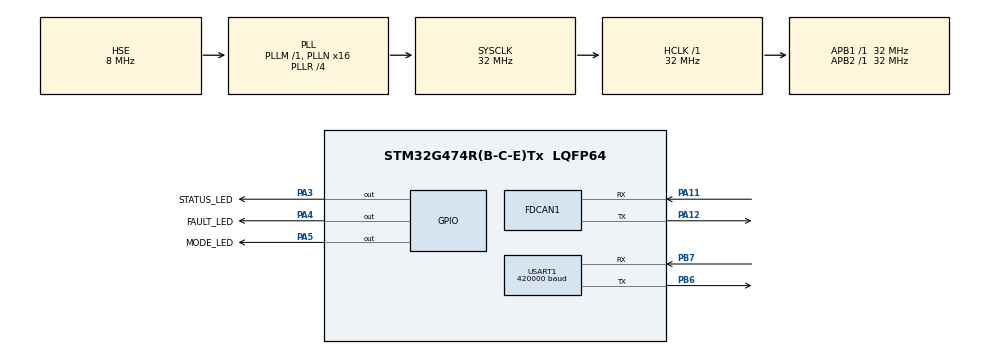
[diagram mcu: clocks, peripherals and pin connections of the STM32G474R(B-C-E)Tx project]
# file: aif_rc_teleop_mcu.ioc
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FDCAN1.CalculateBaudRateNominal=500000
FDCAN1.CalculateTimeBitNominal=2000
FDCAN1.CalculateTimeQuantumNominal=125.0
FDCAN1.DataSyncJumpWidth=2
FDCAN1.NominalPrescaler=1
FDCAN1.NominalTimeSeg1=13
FDCAN1.NominalTimeSeg2=2
FDCAN1.StdFiltersNbr=1
Mcu.Family=STM32G4
Mcu.Name=STM32G474R(B-C-E)Tx
Mcu.Package=LQFP64
NVIC.FDCAN1_IT0_IRQn=true\:0\:0\:false\:false\:true\:true\:true\:true
NVIC.PriorityGroup=NVIC_PRIORITYGROUP_4
NVIC.USART1_IRQn=true\:0\:0\:false\:false\:true\:true\:true\:true
PA11.Mode=FDCAN_Activate
PA11.Signal=FDCAN1_RX
PA12.Mode=FDCAN_Activate
PA12.Signal=FDCAN1_TX
PA13.Mode=Serial_Wire
PA13.Signal=SYS_JTMS-SWDIO
PA14.Mode=Serial_Wire
PA14.Signal=SYS_JTCK-SWCLK
PA3.GPIO_Label=STATUS_LED
PA3.Signal=GPIO_Output
PA4.GPIO_Label=FAULT_LED
PA4.Signal=GPIO_Output
PA5.GPIO_Label=MODE_LED
PA5.Signal=GPIO_Output
PB6.Mode=Asynchronous
PB6.Signal=USART1_TX
PB7.Mode=Asynchronous
PB7.Signal=USART1_RX
PF0-OSC_IN.Mode=HSE-External-Oscillator
PF0-OSC_IN.Signal=RCC_OSC_IN
PF1-OSC_OUT.Mode=HSE-External-Oscillator
PF1-OSC_OUT.Signal=RCC_OSC_OUT
ProjectManager.HeapSize=0x200
ProjectManager.StackSize=0x400
ProjectManager.TargetToolchain=STM32CubeIDE
RCC.ADC12Freq_Value=32000000
RCC.ADC345Freq_Value=32000000
RCC.AHBFreq_Value=32000000
RCC.APB1Freq_Value=32000000
RCC.APB1TimFreq_Value=32000000
RCC.APB2Freq_Value=32000000
RCC.APB2TimFreq_Value=32000000
RCC.CortexFreq_Value=32000000
RCC.EXTERNAL_CLOCK_VALUE=12288000
RCC.FDCANCLockSelection=RCC_FDCANCLKSOURCE_HSE
RCC.HCLKFreq_Value=32000000
RCC.HSE_VALUE=8000000
RCC.HSI48_VALUE=48000000
RCC.HSI_VALUE=16000000
RCC.LSE_VALUE=32768
RCC.PLLN=16
RCC.PLLR=RCC_PLLR_DIV4
RCC.PLLSourceVirtual=RCC_PLLSOURCE_HSE
RCC.SYSCLKFreq_VALUE=32000000
RCC.SYSCLKSource=RCC_SYSCLKSOURCE_PLLCLK
RCC.USBFreq_Value=64000000
RCC.VCOOutputFreq_Value=128000000
USART1.BaudRate=420000
USART1.Mode=MODE_RX
USART1.VirtualMode-Asynchronous=VM_ASYNC
VP_SYS_VS_DBSignals.Mode=DisableDeadBatterySignals
board=custom

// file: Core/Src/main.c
/* USER CODE BEGIN Header */
/**
  ******************************************************************************
  * @file           : main.c
  * @brief          : Main program body
  ******************************************************************************
  * @attention
  *
  * Copyright (c) 2026 STMicroelectronics.
  * All rights reserved.
  *
  * This software is licensed under terms that can be found in the LICENSE file
  * in the root directory of this software component.
  * If no LICENSE file comes with this software, it is provided AS-IS.
  *
  ******************************************************************************
  */
/* USER CODE END Header */
#include "main.h"

/* USER CODE BEGIN Includes */
#include "app.h"

/* USER CODE END Includes */

FDCAN_HandleTypeDef hfdcan1;

UART_HandleTypeDef huart1;

void SystemClock_Config(void);
static void MX_GPIO_Init(void);
static void MX_FDCAN1_Init(void);
static void MX_USART1_UART_Init(void);

int main(void)
{

  /* MCU Configuration--------------------------------------------------------*/

  /* Reset of all peripherals, Initializes the Flash interface and the Systick. */
  HAL_Init();

  /* Configure the system clock */
  SystemClock_Config();

  /* Initialize all configured peripherals */
  MX_GPIO_Init();
  MX_FDCAN1_Init();
  MX_USART1_UART_Init();
  /* USER CODE BEGIN 2 */
  app_init();

  /* USER CODE END 2 */

  /* Infinite loop */
  while (1)
  {

    /* USER CODE BEGIN 3 */
    app_loop();
  }
  /* USER CODE END 3 */
}

void SystemClock_Config(void)
{
  RCC_OscInitTypeDef RCC_OscInitStruct = {0};
  RCC_ClkInitTypeDef RCC_ClkInitStruct = {0};

  /** Configure the main internal regulator output voltage
  */
  HAL_PWREx_ControlVoltageScaling(PWR_REGULATOR_VOLTAGE_SCALE1);

  /** Initializes the RCC Oscillators according to the specified parameters
  * in the RCC_OscInitTypeDef structure.
  */
  RCC_OscInitStruct.OscillatorType = RCC_OSCILLATORTYPE_HSE;
  RCC_OscInitStruct.HSEState = RCC_HSE_ON;
  RCC_OscInitStruct.PLL.PLLState = RCC_PLL_ON;
  RCC_OscInitStruct.PLL.PLLSource = RCC_PLLSOURCE_HSE;
  RCC_OscInitStruct.PLL.PLLM = RCC_PLLM_DIV1;
  RCC_OscInitStruct.PLL.PLLN = 16;
  RCC_OscInitStruct.PLL.PLLP = RCC_PLLP_DIV2;
  RCC_OscInitStruct.PLL.PLLQ = RCC_PLLQ_DIV2;
  RCC_OscInitStruct.PLL.PLLR = RCC_PLLR_DIV4;
  if (HAL_RCC_OscConfig(&RCC_OscInitStruct) != HAL_OK)
  {
    Error_Handler();
  }

  /** Initializes the CPU, AHB and APB buses clocks
  */
  RCC_ClkInitStruct.ClockType = RCC_CLOCKTYPE_HCLK|RCC_CLOCKTYPE_SYSCLK
                              |RCC_CLOCKTYPE_PCLK1|RCC_CLOCKTYPE_PCLK2;
  RCC_ClkInitStruct.SYSCLKSource = RCC_SYSCLKSOURCE_PLLCLK;
  RCC_ClkInitStruct.AHBCLKDivider = RCC_SYSCLK_DIV1;
  RCC_ClkInitStruct.APB1CLKDivider = RCC_HCLK_DIV1;
  RCC_ClkInitStruct.APB2CLKDivider = RCC_HCLK_DIV1;

  if (HAL_RCC_ClockConfig(&RCC_ClkInitStruct, FLASH_LATENCY_1) != HAL_OK)
  {
    Error_Handler();
  }
}

static void MX_FDCAN1_Init(void)
{

  hfdcan1.Instance = FDCAN1;
  hfdcan1.Init.ClockDivider = FDCAN_CLOCK_DIV1;
  hfdcan1.Init.FrameFormat = FDCAN_FRAME_CLASSIC;
  hfdcan1.Init.Mode = FDCAN_MODE_NORMAL;
  hfdcan1.Init.AutoRetransmission = DISABLE;
  hfdcan1.Init.TransmitPause = DISABLE;
  hfdcan1.Init.ProtocolException = DISABLE;
  hfdcan1.Init.NominalPrescaler = 1;
  hfdcan1.Init.NominalSyncJumpWidth = 1;
  hfdcan1.Init.NominalTimeSeg1 = 13;
  hfdcan1.Init.NominalTimeSeg2 = 2;
  hfdcan1.Init.DataPrescaler = 1;
  hfdcan1.Init.DataSyncJumpWidth = 2;
  hfdcan1.Init.DataTimeSeg1 = 1;
  hfdcan1.Init.DataTimeSeg2 = 1;
  hfdcan1.Init.StdFiltersNbr = 1;
  hfdcan1.Init.ExtFiltersNbr = 0;
  hfdcan1.Init.TxFifoQueueMode = FDCAN_TX_FIFO_OPERATION;
  if (HAL_FDCAN_Init(&hfdcan1) != HAL_OK)
  {
    Error_Handler();
  }

}

static void MX_USART1_UART_Init(void)
{

  huart1.Instance = USART1;
  huart1.Init.BaudRate = 420000;
  huart1.Init.WordLength = UART_WORDLENGTH_8B;
  huart1.Init.StopBits = UART_STOPBITS_1;
  huart1.Init.Parity = UART_PARITY_NONE;
  huart1.Init.Mode = UART_MODE_RX;
  huart1.Init.HwFlowCtl = UART_HWCONTROL_NONE;
  huart1.Init.OverSampling = UART_OVERSAMPLING_16;
  huart1.Init.OneBitSampling = UART_ONE_BIT_SAMPLE_DISABLE;
  huart1.Init.ClockPrescaler = UART_PRESCALER_DIV1;
  huart1.AdvancedInit.AdvFeatureInit = UART_ADVFEATURE_NO_INIT;
  if (HAL_UART_Init(&huart1) != HAL_OK)
  {
    Error_Handler();
  }
  if (HAL_UARTEx_SetTxFifoThreshold(&huart1, UART_TXFIFO_THRESHOLD_1_8) != HAL_OK)
  {
    Error_Handler();
  }
  if (HAL_UARTEx_SetRxFifoThreshold(&huart1, UART_RXFIFO_THRESHOLD_1_8) != HAL_OK)
  {
    Error_Handler();
  }
  if (HAL_UARTEx_DisableFifoMode(&huart1) != HAL_OK)
  {
    Error_Handler();
  }

}

static void MX_GPIO_Init(void)
{
  GPIO_InitTypeDef GPIO_InitStruct = {0};

  /* GPIO Ports Clock Enable */
  __HAL_RCC_GPIOC_CLK_ENABLE();
  __HAL_RCC_GPIOF_CLK_ENABLE();
  __HAL_RCC_GPIOG_CLK_ENABLE();
  __HAL_RCC_GPIOA_CLK_ENABLE();
  __HAL_RCC_GPIOB_CLK_ENABLE();
  __HAL_RCC_GPIOD_CLK_ENABLE();

  /*Configure GPIO pin Output Level */
  HAL_GPIO_WritePin(GPIOA, STATUS_LED_Pin|FAULT_LED_Pin|MODE_LED_Pin, GPIO_PIN_RESET);

  /*Configure GPIO pins : PC13 PC14 PC15 PC0
                           PC1 PC2 PC3 PC4
                           PC5 PC6 PC7 PC8
                           PC9 PC10 PC11 PC12 */
  GPIO_InitStruct.Pin = GPIO_PIN_13|GPIO_PIN_14|GPIO_PIN_15|GPIO_PIN_0
                          |GPIO_PIN_1|GPIO_PIN_2|GPIO_PIN_3|GPIO_PIN_4
                          |GPIO_PIN_5|GPIO_PIN_6|GPIO_PIN_7|GPIO_PIN_8
                          |GPIO_PIN_9|GPIO_PIN_10|GPIO_PIN_11|GPIO_PIN_12;
  GPIO_InitStruct.Mode = GPIO_MODE_ANALOG;
  GPIO_InitStruct.Pull = GPIO_NOPULL;
  HAL_GPIO_Init(GPIOC, &GPIO_InitStruct);

  /*Configure GPIO pin : PG10 */
  GPIO_InitStruct.Pin = GPIO_PIN_10;
  GPIO_InitStruct.Mode = GPIO_MODE_ANALOG;
  GPIO_InitStruct.Pull = GPIO_NOPULL;
  HAL_GPIO_Init(GPIOG, &GPIO_InitStruct);

  /*Configure GPIO pins : PA0 PA1 PA2 PA6
                           PA7 PA8 PA9 PA10
                           PA15 */
  GPIO_InitStruct.Pin = GPIO_PIN_0|GPIO_PIN_1|GPIO_PIN_2|GPIO_PIN_6
                          |GPIO_PIN_7|GPIO_PIN_8|GPIO_PIN_9|GPIO_PIN_10
                          |GPIO_PIN_15;
  GPIO_InitStruct.Mode = GPIO_MODE_ANALOG;
  GPIO_InitStruct.Pull = GPIO_NOPULL;
  HAL_GPIO_Init(GPIOA, &GPIO_InitStruct);

  /*Configure GPIO pins : STATUS_LED_Pin FAULT_LED_Pin MODE_LED_Pin */
  GPIO_InitStruct.Pin = STATUS_LED_Pin|FAULT_LED_Pin|MODE_LED_Pin;
  GPIO_InitStruct.Mode = GPIO_MODE_OUTPUT_PP;
  GPIO_InitStruct.Pull = GPIO_NOPULL;
  GPIO_InitStruct.Speed = GPIO_SPEED_FREQ_LOW;
  HAL_GPIO_Init(GPIOA, &GPIO_InitStruct);

  /*Configure GPIO pins : PB0 PB1 PB2 PB10
                           PB11 PB12 PB13 PB14
                           PB15 PB3 PB4 PB5
                           PB8 PB9 */
  GPIO_InitStruct.Pin = GPIO_PIN_0|GPIO_PIN_1|GPIO_PIN_2|GPIO_PIN_10
                          |GPIO_PIN_11|GPIO_PIN_12|GPIO_PIN_13|GPIO_PIN_14
                          |GPIO_PIN_15|GPIO_PIN_3|GPIO_PIN_4|GPIO_PIN_5
                          |GPIO_PIN_8|GPIO_PIN_9;
  GPIO_InitStruct.Mode = GPIO_MODE_ANALOG;
  GPIO_InitStruct.Pull = GPIO_NOPULL;
  HAL_GPIO_Init(GPIOB, &GPIO_InitStruct);

  /*Configure GPIO pin : PD2 */
  GPIO_InitStruct.Pin = GPIO_PIN_2;
  GPIO_InitStruct.Mode = GPIO_MODE_ANALOG;
  GPIO_InitStruct.Pull = GPIO_NOPULL;
  HAL_GPIO_Init(GPIOD, &GPIO_InitStruct);

}

void Error_Handler(void)
{
  /* USER CODE BEGIN Error_Handler_Debug */
  /* User can add his own implementation to report the HAL error return state */
  __HAL_RCC_GPIOA_CLK_ENABLE();
  MODIFY_REG(GPIOA->MODER, GPIO_MODER_MODE4, GPIO_MODER_MODE4_0);
  GPIOA->BSRR = FAULT_LED_Pin;
  __disable_irq();
  while (1)
  {
  }
  /* USER CODE END Error_Handler_Debug */
}
